# WBZ350 register map
Vendor: Microchip
Registers are 32-bit, read-write, reset 0x0 unless marked. A register's access mark holds for its fields unless they carry their own. Addresses are absolute, and some are shared; only a register's first bit layout is shown; [hi:lo] are bit positions; {n}, {i} and the like mark numbered series; 'fields as' and 'values as' point back to an identical list.

## SFR
0xE000E004 ICTR ro reset not defined — Interrupt Controller Type Register (power-on value xxxxxxxxxxxxxxxxxxxxxxxxxxxxxxxx)
  [3:0] INTLINESNUM — Number of interrupt lines supported by NVIC in granularities of 32.

## SysTick
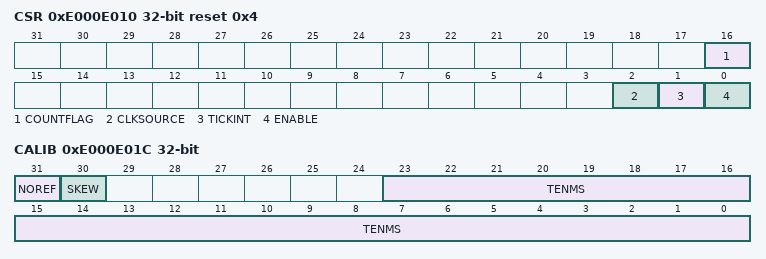
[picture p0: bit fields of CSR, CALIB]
0xE000E010 CSR reset 0x4
  [16] COUNTFLAG — Timer counted to 0 since last read of register
  [2] CLKSOURCE — Clock Source 0=external, 1=processor
    0=External clock; 1=Processor clock
  [1] TICKINT — SysTick Exception Request Enable
    0=Counting down to 0 does not assert the SysTick exception request; 1=Counting down to 0 asserts the SysTick exception request
  [0] ENABLE — SysTick Counter Enable
    0=Counter disabled; 1=Counter enabled
0xE000E014 RVR reset not defined
  [23:0] RELOAD — Value to load into the SysTick Current Value Register when the counter reaches 0
0xE000E018 CVR reset not defined
  [23:0] CURRENT — Current value at the time the register is accessed
0xE000E01C CALIB ro
  [31] NOREF — No Separate Reference Clock
    0=The reference clock is provided; 1=The reference clock is not provided
  [30] SKEW — TENMS is rounded from non-integer ratio
    0=10ms calibration value is exact; 1=10ms calibration value is inexact, because of the clock frequency
  [23:0] TENMS — Reload value to use for 10ms timing

## NVIC
0xE000E100 ISER0
  [31:0] SETENA — Interrupt set enable bits
0xE000E104 ISER1
  [31:0] SETENA — Interrupt set enable bits
0xE000E180 ICER0
  [31:0] CLRENA — Interrupt clear-enable bits
0xE000E184 ICER1
  [31:0] CLRENA — Interrupt clear-enable bits
0xE000E200 ISPR0
  [31:0] SETPEND — Interrupt set-pending bits
0xE000E204 ISPR1
  [31:0] SETPEND — Interrupt set-pending bits
0xE000E280 ICPR0
  [31:0] CLRPEND — Interrupt clear-pending bits
0xE000E284 ICPR1
  [31:0] CLRPEND — Interrupt clear-pending bits
0xE000E300 IABR0
  [31:0] ACTIVE — Interrupt active bits
0xE000E304 IABR1
  [31:0] ACTIVE — Interrupt active bits
{0xE000E400+i} IP{i} 8-bit (i=0..42)
  [2:0] PRI0 — Priority of interrupt n
0xE000EF00 STIR wo reset not defined
  [8:0] INTID — Interrupt ID to trigger

## MPU
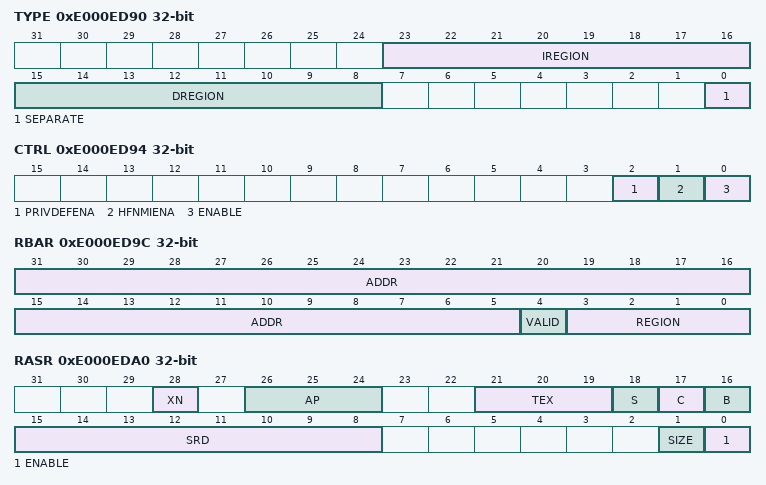
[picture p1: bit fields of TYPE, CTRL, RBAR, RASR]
0xE000ED90 TYPE ro reset not defined
  [23:16] IREGION — Number of Instruction Regions
  [15:8] DREGION — Number of Data Regions
  [0] SEPARATE — Separate instruction and Data Memory MapsRegions
0xE000ED94 CTRL reset not defined
  [2] PRIVDEFENA — Enables privileged software access to default memory map
  [1] HFNMIENA — Enable Hard Fault and NMI handlers
  [0] ENABLE — MPU Enable
0xE000ED98 RNR reset not defined
  [7:0] REGION — Region referenced by RBAR and RASR
0xE000ED9C RBAR reset not defined
  [31:5] ADDR — Region base address
  [4] VALID — Region number valid
  [3:0] REGION — Region number
0xE000EDA0 RASR reset not defined
  [28] XN — Execute Never Attribute
  [26:24] AP — Access Permission
  [21:19] TEX — TEX bit
  [18] S — Shareable bit
  [17] C — Cacheable bit
  [16] B — Bufferable bit
  [15:8] SRD — Sub-region disable
  [1] SIZE — Region Size
  [0] ENABLE — Region Enable
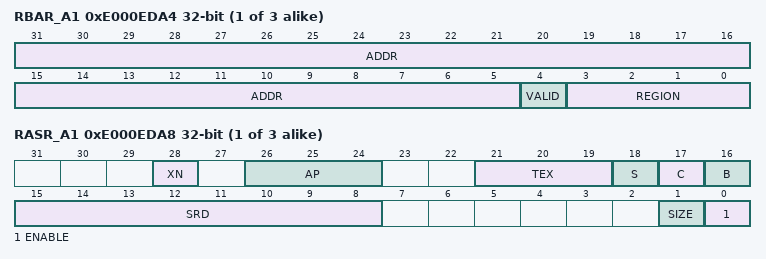
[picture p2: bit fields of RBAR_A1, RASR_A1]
{0xE000ED9C+8i} RBAR_A{i} reset not defined (i=1..3)
  fields as RBAR
{0xE000EDA0+8i} RASR_A{i} reset not defined (i=1..3)
  fields as RASR

## CoreDebug
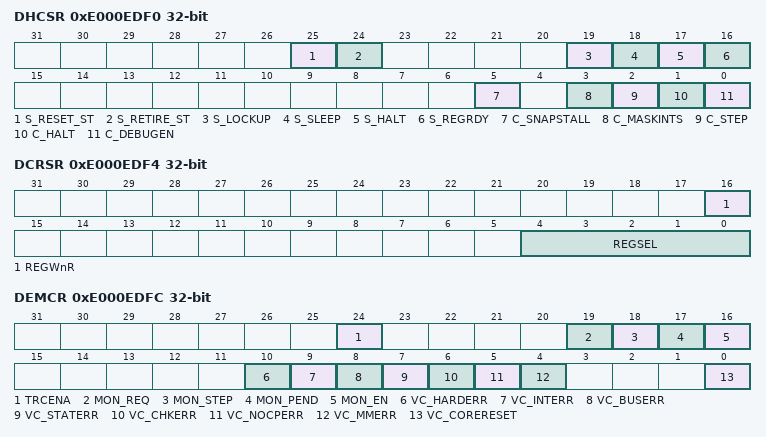
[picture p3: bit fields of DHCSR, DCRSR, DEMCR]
0xE000EDF0 DHCSR reset not defined
  [25] S_RESET_ST, [24] S_RETIRE_ST, [19] S_LOCKUP, [18] S_SLEEP, [17] S_HALT, [16] S_REGRDY, [5] C_SNAPSTALL, [3] C_MASKINTS, [2] C_STEP, [1] C_HALT, [0] C_DEBUGEN
0xE000EDF4 DCRSR wo reset not defined
  [16] REGWnR, [4:0] REGSEL
0xE000EDF8 DCRDR reset not defined
0xE000EDFC DEMCR reset not defined
  [24] TRCENA, [19] MON_REQ, [18] MON_STEP, [17] MON_PEND, [16] MON_EN, [10] VC_HARDERR, [9] VC_INTERR, [8] VC_BUSERR, [7] VC_STATERR, [6] VC_CHKERR, [5] VC_NOCPERR, [4] VC_MMERR, [0] VC_CORERESET
